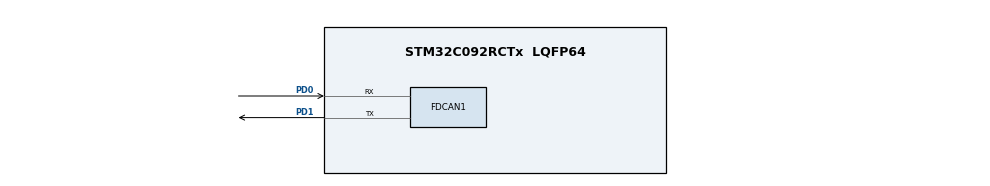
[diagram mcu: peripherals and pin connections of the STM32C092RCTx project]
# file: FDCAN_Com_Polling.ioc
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FDCAN1.AutoRetransmission=ENABLE
FDCAN1.CalculateBaudRateData=1000000
FDCAN1.CalculateBaudRateNominal=1000000
FDCAN1.CalculateTimeBitNominal=1000
FDCAN1.CalculateTimeQuantumNominal=20.833333333333332
FDCAN1.DataSyncJumpWidth=6
FDCAN1.DataTimeSeg1=17
FDCAN1.DataTimeSeg2=6
FDCAN1.FrameFormat=FDCAN_FRAME_FD_BRS
FDCAN1.NominalPrescaler=1
FDCAN1.NominalSyncJumpWidth=12
FDCAN1.NominalTimeSeg1=35
FDCAN1.NominalTimeSeg2=12
FDCAN1.StdFiltersNbr=1
FDCAN1.TransmitPause=ENABLE
Mcu.Family=STM32C0
Mcu.Name=STM32C092RCTx
Mcu.Package=LQFP64
NUCLEO-C092RC.BUTTON=2
NUCLEO-C092RC.LD1=true
NUCLEO-C092RC.LD2=true
NUCLEO-C092RC.VCP=true
PD0.Mode=FDCAN_Activate
PD0.Signal=FDCAN1_RX
PD1.Mode=FDCAN_Activate
PD1.Signal=FDCAN1_TX
ProjectManager.HeapSize=0x200
ProjectManager.StackSize=0x400
ProjectManager.TargetToolchain=EWARM V9.20
RCC.ADCFreq_Value=48000000
RCC.AHBFreq_Value=48000000
RCC.CortexFreq_Value=48000000
RCC.EXTERNAL_CLOCK_VALUE=12288000
RCC.HCLKFreq_Value=48000000
RCC.HSE_VALUE=8000000
RCC.HSISYSCLKDivider=RCC_HSI_DIV1
RCC.HSI_VALUE=48000000
RCC.LSE_VALUE=32768
RCC.SYSCLKFreq_VALUE=48000000
VP_NUCLEO-C092RC_VS_BSP_COMMON.Mode=COMMON
board=NUCLEO-C092RC

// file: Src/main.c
/* USER CODE BEGIN Header */
/**
  ******************************************************************************
  * @file           : main.c
  * @brief          : Main program body
  ******************************************************************************
  * @attention
  *
  * Copyright (c) 2026 STMicroelectronics.
  * All rights reserved.
  *
  * This software is licensed under terms that can be found in the LICENSE file
  * in the root directory of this software component.
  * If no LICENSE file comes with this software, it is provided AS-IS.
  *
  ******************************************************************************
  */
/* USER CODE END Header */
#include "main.h"

/* USER CODE BEGIN PD */
#define TX_ID (0x123)
#define RX_ID (0x123)

/* USER CODE END PD */

COM_InitTypeDef BspCOMInit;

FDCAN_HandleTypeDef hfdcan1;

/* USER CODE BEGIN PV */
FDCAN_RxHeaderTypeDef rxHeader;
FDCAN_TxHeaderTypeDef txHeader;

uint8_t rxData[8];
uint8_t txData[8] = {'H','E','L','L','O',0,0,0};

/* USER CODE END PV */

void SystemClock_Config(void);
static void MX_GPIO_Init(void);
static void MX_FDCAN1_Init(void);

int main(void)
{

  /* MCU Configuration--------------------------------------------------------*/

  /* Reset of all peripherals, Initializes the Flash interface and the Systick. */
  HAL_Init();

  /* Configure the system clock */
  SystemClock_Config();

  /* Initialize all configured peripherals */
  MX_GPIO_Init();
  MX_FDCAN1_Init();
  /* USER CODE BEGIN 2 */
  FDCAN_FilterTypeDef sFilterConfig;

  sFilterConfig.IdType = FDCAN_STANDARD_ID;
  sFilterConfig.FilterIndex = 0;
  sFilterConfig.FilterType = FDCAN_FILTER_MASK;
  sFilterConfig.FilterConfig = FDCAN_FILTER_TO_RXFIFO0;
  sFilterConfig.FilterID1 = RX_ID;
  sFilterConfig.FilterID2 = 0x7FF;

  if (HAL_FDCAN_ConfigFilter(&hfdcan1, &sFilterConfig) != HAL_OK)
  {
    Error_Handler();
  }

  if (HAL_FDCAN_ConfigGlobalFilter(&hfdcan1,
                                 FDCAN_REJECT, FDCAN_REJECT,
                                 FDCAN_FILTER_REMOTE, FDCAN_FILTER_REMOTE) != HAL_OK)
  {
    Error_Handler();
  }

  txHeader.Identifier = TX_ID;
  txHeader.IdType = FDCAN_STANDARD_ID;
  txHeader.TxFrameType = FDCAN_DATA_FRAME;
  txHeader.DataLength = FDCAN_DLC_BYTES_8;
  txHeader.ErrorStateIndicator = FDCAN_ESI_ACTIVE;
  txHeader.BitRateSwitch = FDCAN_BRS_ON;
  txHeader.FDFormat = FDCAN_FD_CAN;
  txHeader.TxEventFifoControl = FDCAN_NO_TX_EVENTS;
  txHeader.MessageMarker = 0;

  if (HAL_FDCAN_ConfigTxDelayCompensation(&hfdcan1,
      (hfdcan1.Init.DataPrescaler * hfdcan1.Init.DataTimeSeg1), 0) != HAL_OK)
  {
    Error_Handler();
  }

  if (HAL_FDCAN_EnableTxDelayCompensation(&hfdcan1) != HAL_OK)
  {
    Error_Handler();
  }

  if (HAL_FDCAN_Start(&hfdcan1) != HAL_OK)
  {
    Error_Handler();
  }

  /* USER CODE END 2 */

  /* Initialize leds */
  BSP_LED_Init(LED_GREEN);
  BSP_LED_Init(LED_BLUE);

  /* Initialize User push-button without interrupt mode. */
  BSP_PB_Init(BUTTON_USER, BUTTON_MODE_GPIO);

  /* Initialize COM1 port (115200, 8 bits (7-bit data + 1 stop bit), no parity */
  BspCOMInit.BaudRate   = 115200;
  BspCOMInit.WordLength = COM_WORDLENGTH_8B;
  BspCOMInit.StopBits   = COM_STOPBITS_1;
  BspCOMInit.Parity     = COM_PARITY_NONE;
  BspCOMInit.HwFlowCtl  = COM_HWCONTROL_NONE;
  if (BSP_COM_Init(COM1, &BspCOMInit) != BSP_ERROR_NONE)
  {
    Error_Handler();
  }

  /* Infinite loop */
  /* USER CODE BEGIN WHILE */
  while (1)
  {
    if (BSP_PB_GetState(BUTTON_USER) == GPIO_PIN_RESET)
    {
      BSP_LED_Off(LED_GREEN);

      if (HAL_FDCAN_AddMessageToTxFifoQ(&hfdcan1, &txHeader, txData) != HAL_OK)
      {
        Error_Handler();
      }

      printf("Sent: %s\r\n", txData);
      HAL_Delay(300);
    }

    if (HAL_FDCAN_GetRxFifoFillLevel(&hfdcan1, FDCAN_RX_FIFO0) > 0)
    {
      memset(rxData, 0, sizeof(rxData));

      if (HAL_FDCAN_GetRxMessage(&hfdcan1, FDCAN_RX_FIFO0, &rxHeader, rxData) != HAL_OK)
      {
        Error_Handler();
      }

      printf("Received ID: 0x%lx\r\n", rxHeader.Identifier);
      printf("Message: %s\r\n", rxData);

      BSP_LED_On(LED_GREEN);
    }

    /* USER CODE END WHILE */

  }
}

void SystemClock_Config(void)
{
  RCC_OscInitTypeDef RCC_OscInitStruct = {0};
  RCC_ClkInitTypeDef RCC_ClkInitStruct = {0};

  __HAL_FLASH_SET_LATENCY(FLASH_LATENCY_1);

  /** Initializes the RCC Oscillators according to the specified parameters
  * in the RCC_OscInitTypeDef structure.
  */
  RCC_OscInitStruct.OscillatorType = RCC_OSCILLATORTYPE_HSI;
  RCC_OscInitStruct.HSIState = RCC_HSI_ON;
  RCC_OscInitStruct.HSIDiv = RCC_HSI_DIV1;
  RCC_OscInitStruct.HSICalibrationValue = RCC_HSICALIBRATION_DEFAULT;
  if (HAL_RCC_OscConfig(&RCC_OscInitStruct) != HAL_OK)
  {
    Error_Handler();
  }

  /** Initializes the CPU, AHB and APB buses clocks
  */
  RCC_ClkInitStruct.ClockType = RCC_CLOCKTYPE_HCLK|RCC_CLOCKTYPE_SYSCLK
                              |RCC_CLOCKTYPE_PCLK1;
  RCC_ClkInitStruct.SYSCLKSource = RCC_SYSCLKSOURCE_HSI;
  RCC_ClkInitStruct.SYSCLKDivider = RCC_SYSCLK_DIV1;
  RCC_ClkInitStruct.AHBCLKDivider = RCC_HCLK_DIV1;
  RCC_ClkInitStruct.APB1CLKDivider = RCC_APB1_DIV1;

  if (HAL_RCC_ClockConfig(&RCC_ClkInitStruct, FLASH_LATENCY_1) != HAL_OK)
  {
    Error_Handler();
  }
}

static void MX_FDCAN1_Init(void)
{

  hfdcan1.Instance = FDCAN1;
  hfdcan1.Init.ClockDivider = FDCAN_CLOCK_DIV1;
  hfdcan1.Init.FrameFormat = FDCAN_FRAME_FD_BRS;
  hfdcan1.Init.Mode = FDCAN_MODE_NORMAL;
  hfdcan1.Init.AutoRetransmission = ENABLE;
  hfdcan1.Init.TransmitPause = ENABLE;
  hfdcan1.Init.ProtocolException = DISABLE;
  hfdcan1.Init.NominalPrescaler = 1;
  hfdcan1.Init.NominalSyncJumpWidth = 12;
  hfdcan1.Init.NominalTimeSeg1 = 35;
  hfdcan1.Init.NominalTimeSeg2 = 12;
  hfdcan1.Init.DataPrescaler = 1;
  hfdcan1.Init.DataSyncJumpWidth = 6;
  hfdcan1.Init.DataTimeSeg1 = 17;
  hfdcan1.Init.DataTimeSeg2 = 6;
  hfdcan1.Init.StdFiltersNbr = 1;
  hfdcan1.Init.ExtFiltersNbr = 0;
  hfdcan1.Init.TxFifoQueueMode = FDCAN_TX_FIFO_OPERATION;
  if (HAL_FDCAN_Init(&hfdcan1) != HAL_OK)
  {
    Error_Handler();
  }

}

static void MX_GPIO_Init(void)
{

  /* GPIO Ports Clock Enable */
  __HAL_RCC_GPIOD_CLK_ENABLE();

}

void Error_Handler(void)
{
  __disable_irq();
  while (1)
  {
  }
}
